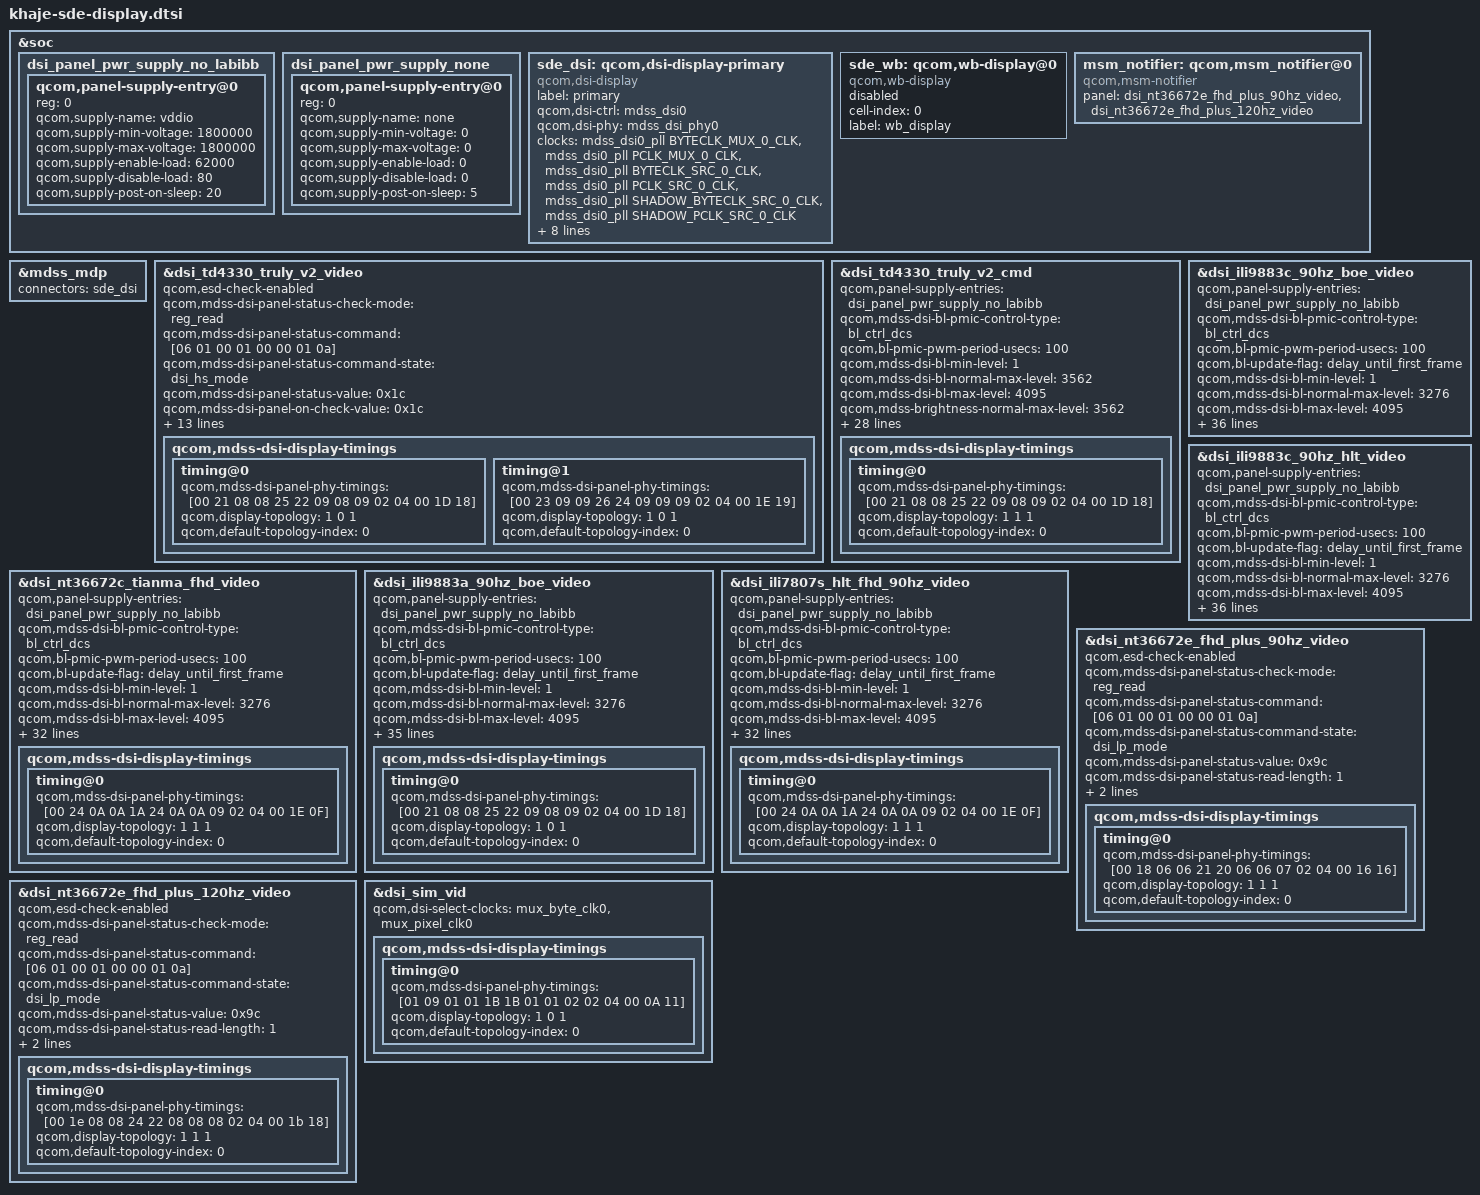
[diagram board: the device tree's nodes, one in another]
#include "dsi-panel-td4330-truly-v2-singlemipi-fhd-cmd.dtsi"
#include "dsi-panel-td4330-truly-v2-singlemipi-fhd-vid.dtsi"
#include "dsi-panel-nt36672e-fhd-plus-90hz-video.dtsi"
#include "../oplus/golf/dsi-panel-ili9883a-90hz-boe-fhd-video.dtsi"
#include "../oplus/golf/dsi-panel-ili7807s-hlt-fhd-vedio.dtsi"
#include "../oplus/golf/dsi-panel-nt36672c-tianma-fhd-video.dtsi"
#include "../oplus/zhaoyun-a/dsi-panel-ili9883c-90hz-boe-hd-video.dtsi"
#include "../oplus/zhaoyun-a/dsi-panel-ili9883c-90hz-hlt-hd-video.dtsi"
#include "dsi-panel-nt36672e-fhd-plus-120hz-video.dtsi"
#include "dsi-panel-sim-video.dtsi"
#include "dsi-panel-oplus_s6e8fc1fe-samsung-fhd-video.dtsi"
#include "dsi-panel-oplus-samsung-s6e3fc3-1080-2400-dsi-cmd.dtsi"
#include <dt-bindings/clock/mdss-7nm-pll-clk.h>

&soc {
	dsi_panel_pwr_supply_no_labibb: dsi_panel_pwr_supply_no_labibb {
		#address-cells = <1>;
		#size-cells = <0>;

		qcom,panel-supply-entry@0 {
			reg = <0>;
			qcom,supply-name = "vddio";
			qcom,supply-min-voltage = <1800000>;
			qcom,supply-max-voltage = <1800000>;
			qcom,supply-enable-load = <62000>;
			qcom,supply-disable-load = <80>;
			qcom,supply-post-on-sleep = <20>;
		};
	};

	dsi_panel_pwr_supply_none: dsi_panel_pwr_supply_none {
		#address-cells = <1>;
		#size-cells = <0>;

		qcom,panel-supply-entry@0 {
			reg = <0>;
			qcom,supply-name = "none";
			qcom,supply-min-voltage = <0>;
			qcom,supply-max-voltage = <0>;
			qcom,supply-enable-load = <0>;
			qcom,supply-disable-load = <0>;
			qcom,supply-post-on-sleep = <5>;
		};
	};

	sde_dsi: qcom,dsi-display-primary {
		compatible = "qcom,dsi-display";
		label = "primary";
		qcom,dsi-ctrl = <&mdss_dsi0>;
		qcom,dsi-phy = <&mdss_dsi_phy0>;

		clocks = <&mdss_dsi0_pll BYTECLK_MUX_0_CLK>,
			 <&mdss_dsi0_pll PCLK_MUX_0_CLK>,
			 <&mdss_dsi0_pll BYTECLK_SRC_0_CLK>,
			 <&mdss_dsi0_pll PCLK_SRC_0_CLK>,
			 <&mdss_dsi0_pll SHADOW_BYTECLK_SRC_0_CLK>,
			 <&mdss_dsi0_pll SHADOW_PCLK_SRC_0_CLK>;
		clock-names = "mux_byte_clk0", "mux_pixel_clk0",
			"src_byte_clk0", "src_pixel_clk0",
			"shadow_byte_clk0", "shadow_pixel_clk0";
		pinctrl-names = "panel_active", "panel_suspend";
		pinctrl-0 = <&sde_dsi_active &sde_te_active>;
		pinctrl-1 = <&sde_dsi_suspend &sde_te_suspend>;

		qcom,platform-te-gpio = <&tlmm 81 0>;
		qcom,panel-te-source = <0>;

		vddio-supply = <&L9A>;
		qcom,mdp = <&mdss_mdp>;

		qcom,dsi-default-panel =
			<&dsi_nt36672c_tianma_fhd_video>;
	};

	sde_wb: qcom,wb-display@0 {
		status = "disabled";
		compatible = "qcom,wb-display";
		cell-index = <0>;
		label = "wb_display";
	};

	msm_notifier: qcom,msm_notifier@0 {
		compatible = "qcom,msm-notifier";
		panel = <&dsi_nt36672e_fhd_plus_90hz_video
			&dsi_nt36672e_fhd_plus_120hz_video>;
	};
};

&mdss_mdp {
	connectors = <&sde_dsi>;
};

&dsi_td4330_truly_v2_video {
	qcom,esd-check-enabled;
	qcom,mdss-dsi-panel-status-check-mode = "reg_read";
	qcom,mdss-dsi-panel-status-command = [06 01 00 01 00 00 01 0a];
	qcom,mdss-dsi-panel-status-command-state = "dsi_hs_mode";
	qcom,mdss-dsi-panel-status-value = <0x1c>;
	qcom,mdss-dsi-panel-on-check-value = <0x1c>;
	qcom,mdss-dsi-panel-status-read-length = <1>;
	qcom,dsi-supported-dfps-list = <60 55 48>;
	qcom,mdss-dsi-pan-enable-dynamic-fps;
	qcom,mdss-dsi-pan-fps-update =
			"dfps_immediate_porch_mode_vfp";
	qcom,dsi-select-clocks = "mux_byte_clk0", "mux_pixel_clk0",
				"src_byte_clk0", "src_pixel_clk0",
				"shadow_byte_clk0", "shadow_pixel_clk0";
	qcom,dsi-dyn-clk-enable;
	qcom,dsi-dyn-clk-list =
		<976190400 988392784 984325320 980257864>;
	qcom,dsi-dyn-clk-type = "constant-fps-adjust-vfp";
	qcom,mdss-dsi-display-timings {
		timing@0 {
			qcom,mdss-dsi-panel-phy-timings = [00 21 08 08 25 22 09
					08 09 02 04 00 1D 18];
			qcom,display-topology = <1 0 1>;
			qcom,default-topology-index = <0>;
		};

		timing@1 {
			qcom,mdss-dsi-panel-phy-timings = [00 23 09 09 26 24 09
					09 09 02 04 00 1E 19];
			qcom,display-topology = <1 0 1>;
			qcom,default-topology-index = <0>;
		};
	};
};

&dsi_td4330_truly_v2_cmd {
	qcom,panel-supply-entries = <&dsi_panel_pwr_supply_no_labibb>;
	qcom,mdss-dsi-bl-pmic-control-type = "bl_ctrl_dcs";
	qcom,bl-pmic-pwm-period-usecs = <100>;
	qcom,mdss-dsi-bl-min-level = <1>;
	qcom,mdss-dsi-bl-normal-max-level = <3562>;
	qcom,mdss-dsi-bl-max-level = <4095>;
	qcom,mdss-brightness-normal-max-level = <3562>;
	qcom,mdss-brightness-max-level = <4095>;
	qcom,mdss-brightness-default-level = <400>;
	qcom,platform-te-gpio = <&tlmm 81 0>;
	qcom,platform-reset-gpio = <&tlmm 82 0>;
	qcom,platform-panel-vddi-gpio = <&tlmm 103 0>;
	qcom,platform-panel-P5V-gpio = <&tlmm 43 0>;
	qcom,platform-panel-N5V-gpio = <&tlmm 54 0>;

	qcom,mdss-dsi-t-clk-post = <0x18>;
	qcom,mdss-dsi-t-clk-pre = <0x1D>;

	qcom,dsi-supported-dfps-list = <90 60>;
	qcom,mdss-dsi-pan-enable-dynamic-fps;
	qcom,mdss-dsi-pan-fps-update =
		"dfps_immediate_porch_mode_vfp";
	qcom,mdss-dsi-min-refresh-rate = <60>;
	qcom,mdss-dsi-max-refresh-rate = <90>;
	oplus,dfps-idle-off;
	qcom,esd-check-enabled;
	qcom,mdss-dsi-panel-status-check-mode = "reg_read";
	qcom,mdss-dsi-panel-status-command = [06 01 00 01 00 00 01 0A];
	qcom,mdss-dsi-panel-status-command-state = "dsi_lp_mode";
	qcom,mdss-dsi-panel-status-value = <0x9C>;
	qcom,mdss-dsi-panel-on-check-value = <0x9C>;
	qcom,mdss-dsi-panel-status-read-length = <1>;
	qcom,dsi-select-clocks = "mux_byte_clk0", "mux_pixel_clk0";
	qcom,mdss-dsi-display-timings {
		timing@0 {
			qcom,mdss-dsi-panel-phy-timings = [00 21 08 08 25 22 09
					08 09 02 04 00 1D 18];
			qcom,display-topology = <1 1 1>;
			qcom,default-topology-index = <0>;
		};
	};
};
&dsi_nt36672c_tianma_fhd_video {
	qcom,panel-supply-entries = <&dsi_panel_pwr_supply_no_labibb>;
	qcom,mdss-dsi-bl-pmic-control-type = "bl_ctrl_dcs";
	qcom,bl-pmic-pwm-period-usecs = <100>;
	qcom,bl-update-flag = "delay_until_first_frame";
	qcom,mdss-dsi-bl-min-level = <1>;
	qcom,mdss-dsi-bl-normal-max-level = <3276>;
	qcom,mdss-dsi-bl-max-level = <4095>;
	qcom,mdss-brightness-normal-max-level = <3276>;
	qcom,mdss-brightness-max-level = <4095>;
	qcom,mdss-brightness-default-level = <930>;
	qcom,platform-te-gpio = <&tlmm 81 0>;
	qcom,platform-reset-gpio = <&tlmm 82 0>;
	qcom,platform-panel-vddi-gpio = <&tlmm 103 0>;
	qcom,platform-panel-P5V-gpio = <&tlmm 43 0>;
	qcom,platform-panel-N5V-gpio = <&tlmm 54 0>;
	oplus,mdss-dsi-vspn-voltage = <5500>;
	oplus,mdss-dsi-gamma-switch-enabled;
	qcom,mdss-dsi-t-clk-post = <0x0F>;
	qcom,mdss-dsi-t-clk-pre = <0x1E>;

	qcom,dsi-supported-dfps-list = <90 60 50 48 45 30>;
	qcom,mdss-dsi-pan-enable-dynamic-fps;
	qcom,mdss-dsi-pan-fps-update =
		"dfps_immediate_porch_mode_vfp";
	qcom,mdss-dsi-min-refresh-rate = <30>;
	qcom,mdss-dsi-max-refresh-rate = <90>;
	oppo,dfps-idle-off;
	qcom,esd-check-enabled;
	qcom,mdss-dsi-panel-status-check-mode = "reg_read";
	qcom,mdss-dsi-panel-status-command = [06 01 00 01 00 00 01 0A];
	qcom,mdss-dsi-panel-status-command-state = "dsi_lp_mode";
	qcom,mdss-dsi-panel-status-value = <0x9C>;
	qcom,mdss-dsi-panel-on-check-value = <0x9C>;
	qcom,mdss-dsi-panel-status-read-length = <1>;
	qcom,dsi-select-clocks = "mux_byte_clk0", "mux_pixel_clk0";
	qcom,mdss-dsi-display-timings {
		timing@0 {
			qcom,mdss-dsi-panel-phy-timings = [00 24 0A 0A 1A 24 0A
					0A 09 02 04 00 1E 0F];
			qcom,display-topology = <1 1 1>;
			qcom,default-topology-index = <0>;
		};
	};
};

&dsi_ili9883a_90hz_boe_video {
	qcom,panel-supply-entries = <&dsi_panel_pwr_supply_no_labibb>;
	qcom,mdss-dsi-bl-pmic-control-type = "bl_ctrl_dcs";
	qcom,bl-pmic-pwm-period-usecs = <100>;
	qcom,bl-update-flag = "delay_until_first_frame";
	qcom,mdss-dsi-bl-min-level = <1>;
	qcom,mdss-dsi-bl-normal-max-level = <3276>;
	qcom,mdss-dsi-bl-max-level = <4095>;
	qcom,mdss-brightness-normal-max-level = <3276>;
	qcom,mdss-brightness-max-level = <4095>;
	qcom,mdss-brightness-default-level = <930>;
	qcom,platform-te-gpio = <&tlmm 81 0>;
	qcom,platform-reset-gpio = <&tlmm 82 0>;
	//qcom,platform-panel-vddi-gpio = <&tlmm 103 0>;
	qcom,platform-panel-P5V-gpio = <&tlmm 43 0>;
	qcom,platform-panel-N5V-gpio = <&tlmm 54 0>;
	oplus,mdss-dsi-vspn-voltage = <6000>;
	oplus,mdss-dsi-gamma-switch-enabled;
	qcom,mdss-dsi-t-clk-post = <0x0D>;
	qcom,mdss-dsi-t-clk-pre = <0x2D>;
	qcom,dsi-supported-dfps-list = <60 90>;
	qcom,mdss-dsi-pan-enable-dynamic-fps;
	qcom,mdss-dsi-pan-fps-update =
		"dfps_immediate_porch_mode_vfp";
	qcom,mdss-dsi-min-refresh-rate = <60>;
	qcom,mdss-dsi-max-refresh-rate = <90>;
	oplus,dfps-idle-off;
	qcom,esd-check-enabled;
	qcom,mdss-dsi-panel-status-check-mode = "reg_read";
	qcom,mdss-dsi-panel-status-command = [06 01 00 01 00 00 01 09];
	qcom,mdss-dsi-panel-status-command-state = "dsi_lp_mode";
	qcom,mdss-dsi-panel-status-value = <0x80 0x03 0x06>;
	//qcom,mdss-dsi-panel-on-check-value = <0x9c>;
	qcom,mdss-dsi-panel-status-read-length = <3>;
	qcom,dsi-select-clocks = "mux_byte_clk0", "mux_pixel_clk0",
				"src_byte_clk0", "src_pixel_clk0",
				"shadow_byte_clk0", "shadow_pixel_clk0";
	qcom,dsi-dyn-clk-enable;
	qcom,dsi-dyn-clk-list =
		<833898240 844321968>;
	qcom,dsi-dyn-clk-type = "constant-fps-adjust-vfp";

	qcom,mdss-dsi-display-timings {
		timing@0{
			qcom,mdss-dsi-panel-phy-timings =[00 21 08 08 25 22 09
					08 09 02 04 00 1D 18];

			qcom,display-topology = <1 0 1>;
			qcom,default-topology-index = <0>;
		};
	};
};

&dsi_ili9883c_90hz_boe_video {
	qcom,panel-supply-entries = <&dsi_panel_pwr_supply_no_labibb>;
	qcom,mdss-dsi-bl-pmic-control-type = "bl_ctrl_dcs";
	qcom,bl-pmic-pwm-period-usecs = <100>;
	qcom,bl-update-flag = "delay_until_first_frame";
	qcom,mdss-dsi-bl-min-level = <1>;
	qcom,mdss-dsi-bl-normal-max-level = <3276>;
	qcom,mdss-dsi-bl-max-level = <4095>;
	qcom,mdss-brightness-normal-max-level = <3276>;
	qcom,mdss-brightness-max-level = <4095>;
	qcom,mdss-brightness-default-level = <930>;
	qcom,platform-te-gpio = <&tlmm 81 0>;
	qcom,platform-reset-gpio = <&tlmm 82 0>;
	qcom,platform-panel-P5V-gpio = <&tlmm 43 0>;
	qcom,platform-panel-N5V-gpio = <&tlmm 54 0>;
	qcom,platform-panel-vddi-gpio = <&tlmm 103 0>;
	oplus,mdss-dsi-vspn-voltage = <6000>;
	oplus,mdss-dsi-gamma-switch-enabled;
	qcom,mdss-dsi-t-clk-post = <0x0C>;
	qcom,mdss-dsi-t-clk-pre = <0x19>;
	qcom,dsi-supported-dfps-list = <60 90>;
	qcom,mdss-dsi-pan-enable-dynamic-fps;
	qcom,mdss-dsi-pan-fps-update =
		"dfps_immediate_porch_mode_vfp";
	qcom,mdss-dsi-min-refresh-rate = <60>;
	qcom,mdss-dsi-max-refresh-rate = <90>;
	oplus,dfps-idle-off;
	qcom,esd-check-enabled;
	qcom,mdss-dsi-panel-status-check-mode = "reg_read";
	qcom,mdss-dsi-panel-status-command = [06 01 00 01 00 00 01 09];
	qcom,mdss-dsi-panel-status-command-state = "dsi_lp_mode";
	qcom,mdss-dsi-panel-status-value = <0x80 0x03 0x06>;
	//qcom,mdss-dsi-panel-on-check-value = <0x9c>;
	qcom,mdss-dsi-panel-status-read-length = <3>;
	qcom,dsi-select-clocks = "mux_byte_clk0", "mux_pixel_clk0",
				"src_byte_clk0", "src_pixel_clk0",
				"shadow_byte_clk0", "shadow_pixel_clk0";
	qcom,dsi-dyn-clk-enable;
	qcom,dsi-dyn-clk-list =
		<834158520 844585504>;
	qcom,dsi-dyn-clk-type = "constant-fps-adjust-vfp";
};

&dsi_ili9883c_90hz_hlt_video {
	qcom,panel-supply-entries = <&dsi_panel_pwr_supply_no_labibb>;
	qcom,mdss-dsi-bl-pmic-control-type = "bl_ctrl_dcs";
	qcom,bl-pmic-pwm-period-usecs = <100>;
	qcom,bl-update-flag = "delay_until_first_frame";
	qcom,mdss-dsi-bl-min-level = <1>;
	qcom,mdss-dsi-bl-normal-max-level = <3276>;
	qcom,mdss-dsi-bl-max-level = <4095>;
	qcom,mdss-brightness-normal-max-level = <3276>;
	qcom,mdss-brightness-max-level = <4095>;
	qcom,mdss-brightness-default-level = <930>;
	qcom,platform-te-gpio = <&tlmm 81 0>;
	qcom,platform-reset-gpio = <&tlmm 82 0>;
	qcom,platform-panel-P5V-gpio = <&tlmm 43 0>;
	qcom,platform-panel-N5V-gpio = <&tlmm 54 0>;
	qcom,platform-panel-vddi-gpio = <&tlmm 103 0>;
	oplus,mdss-dsi-vspn-voltage = <6000>;
	oplus,mdss-dsi-gamma-switch-enabled;
	qcom,mdss-dsi-t-clk-post = <0x0C>;
	qcom,mdss-dsi-t-clk-pre = <0x19>;
	qcom,dsi-supported-dfps-list = <60 90>;
	qcom,mdss-dsi-pan-enable-dynamic-fps;
	qcom,mdss-dsi-pan-fps-update =
		"dfps_immediate_porch_mode_vfp";
	qcom,mdss-dsi-min-refresh-rate = <60>;
	qcom,mdss-dsi-max-refresh-rate = <90>;
	oplus,dfps-idle-off;
	qcom,esd-check-enabled;
	qcom,mdss-dsi-panel-status-check-mode = "reg_read";
	qcom,mdss-dsi-panel-status-command = [06 01 00 01 00 00 01 09];
	qcom,mdss-dsi-panel-status-command-state = "dsi_lp_mode";
	qcom,mdss-dsi-panel-status-value = <0x80 0x03 0x06>;
	//qcom,mdss-dsi-panel-on-check-value = <0x9c>;
	qcom,mdss-dsi-panel-status-read-length = <3>;
	qcom,dsi-select-clocks = "mux_byte_clk0", "mux_pixel_clk0",
				"src_byte_clk0", "src_pixel_clk0",
				"shadow_byte_clk0", "shadow_pixel_clk0";
	qcom,dsi-dyn-clk-enable;
	qcom,dsi-dyn-clk-list =
		<834158520 844585504>;
	qcom,dsi-dyn-clk-type = "constant-fps-adjust-vfp";
};

&dsi_ili7807s_hlt_fhd_90hz_video {
	qcom,panel-supply-entries = <&dsi_panel_pwr_supply_no_labibb>;
	qcom,mdss-dsi-bl-pmic-control-type = "bl_ctrl_dcs";
	qcom,bl-pmic-pwm-period-usecs = <100>;
	qcom,bl-update-flag = "delay_until_first_frame";
	qcom,mdss-dsi-bl-min-level = <1>;
	qcom,mdss-dsi-bl-normal-max-level = <3276>;
	qcom,mdss-dsi-bl-max-level = <4095>;
	qcom,mdss-brightness-normal-max-level = <3276>;
	qcom,mdss-brightness-max-level = <4095>;
	qcom,mdss-brightness-default-level = <930>;
	qcom,platform-te-gpio = <&tlmm 81 0>;
	qcom,platform-reset-gpio = <&tlmm 82 0>;
	qcom,platform-panel-vddi-gpio = <&tlmm 103 0>;
	qcom,platform-panel-P5V-gpio = <&tlmm 43 0>;
	qcom,platform-panel-N5V-gpio = <&tlmm 54 0>;
	oplus,mdss-dsi-vspn-voltage = <5500>;
	oplus,mdss-dsi-gamma-switch-enabled;
	qcom,mdss-dsi-t-clk-post = <0x0D>;
	qcom,mdss-dsi-t-clk-pre = <0x2D>;
	qcom,dsi-supported-dfps-list = <90 60 50 48 45 30>;
	qcom,mdss-dsi-pan-enable-dynamic-fps;
	qcom,mdss-dsi-pan-fps-update =
		"dfps_immediate_porch_mode_vfp";
	qcom,mdss-dsi-min-refresh-rate = <30>;
	qcom,mdss-dsi-max-refresh-rate = <90>;
	oppo,dfps-idle-off;
	qcom,esd-check-enabled;
	qcom,mdss-dsi-panel-status-check-mode = "reg_read";
	qcom,mdss-dsi-panel-status-command = [06 01 00 01 00 00 01 09];
	qcom,mdss-dsi-panel-status-command-state = "dsi_lp_mode";
	qcom,mdss-dsi-panel-status-value = <0x80 0x03 0x06>;
	//qcom,mdss-dsi-panel-on-check-value = <0x9C>;
	qcom,mdss-dsi-panel-status-read-length = <3>;
	qcom,dsi-select-clocks = "mux_byte_clk0", "mux_pixel_clk0";
	qcom,mdss-dsi-display-timings {
		timing@0{
			qcom,mdss-dsi-panel-phy-timings =[00 24 0A 0A 1A 24 0A
					0A 09 02 04 00 1E 0F];

			qcom,display-topology = <1 1 1>;
			qcom,default-topology-index = <0>;
		};
	};
};

&dsi_nt36672e_fhd_plus_90hz_video {
	qcom,esd-check-enabled;
	qcom,mdss-dsi-panel-status-check-mode = "reg_read";
	qcom,mdss-dsi-panel-status-command = [06 01 00 01 00 00 01 0a];
	qcom,mdss-dsi-panel-status-command-state = "dsi_lp_mode";
	qcom,mdss-dsi-panel-status-value = <0x9c>;
	qcom,mdss-dsi-panel-status-read-length = <1>;
	qcom,dsi-select-clocks = "mux_byte_clk0", "mux_pixel_clk0";
	qcom,mdss-dsi-display-timings {
		timing@0 {
			qcom,mdss-dsi-panel-phy-timings = [00 18 06 06 21 20 06
					06 07 02 04 00 16 16];
			qcom,display-topology = <1 1 1>;
			qcom,default-topology-index = <0>;
		};
	};
};

&dsi_nt36672e_fhd_plus_120hz_video {
	qcom,esd-check-enabled;
	qcom,mdss-dsi-panel-status-check-mode = "reg_read";
	qcom,mdss-dsi-panel-status-command = [06 01 00 01 00 00 01 0a];
	qcom,mdss-dsi-panel-status-command-state = "dsi_lp_mode";
	qcom,mdss-dsi-panel-status-value = <0x9c>;
	qcom,mdss-dsi-panel-status-read-length = <1>;
	qcom,dsi-select-clocks = "mux_byte_clk0", "mux_pixel_clk0";
	qcom,mdss-dsi-display-timings {
		timing@0 {
			qcom,mdss-dsi-panel-phy-timings = [00 1e 08 08 24 22 08
					08 08 02 04 00 1b 18];
			qcom,display-topology = <1 1 1>;
			qcom,default-topology-index = <0>;
		};
	};
};

&dsi_sim_vid {
	qcom,dsi-select-clocks = "mux_byte_clk0", "mux_pixel_clk0";
	qcom,mdss-dsi-display-timings {
		timing@0 {
			qcom,mdss-dsi-panel-phy-timings = [01 09 01 01 1B 1B 01
					01 02 02 04 00 0A 11];
			qcom,display-topology = <1 0 1>;
			qcom,default-topology-index = <0>;
		};
	};
};
